# H616 register map
Vendor: Allwinner; Series: H616; File version: 0.1
CPU: other 0, little endian, MPU, no FPU, 0 interrupt priority bits
Registers are 32-bit, read-write, reset 0x0 unless marked. A register's access mark holds for its fields unless they carry their own. Offsets are from the block's base; [hi:lo] are bit positions; lines under a group give offsets from that group; {n}, {i} and the like mark numbered series.

## DMA
Base 0x03002000
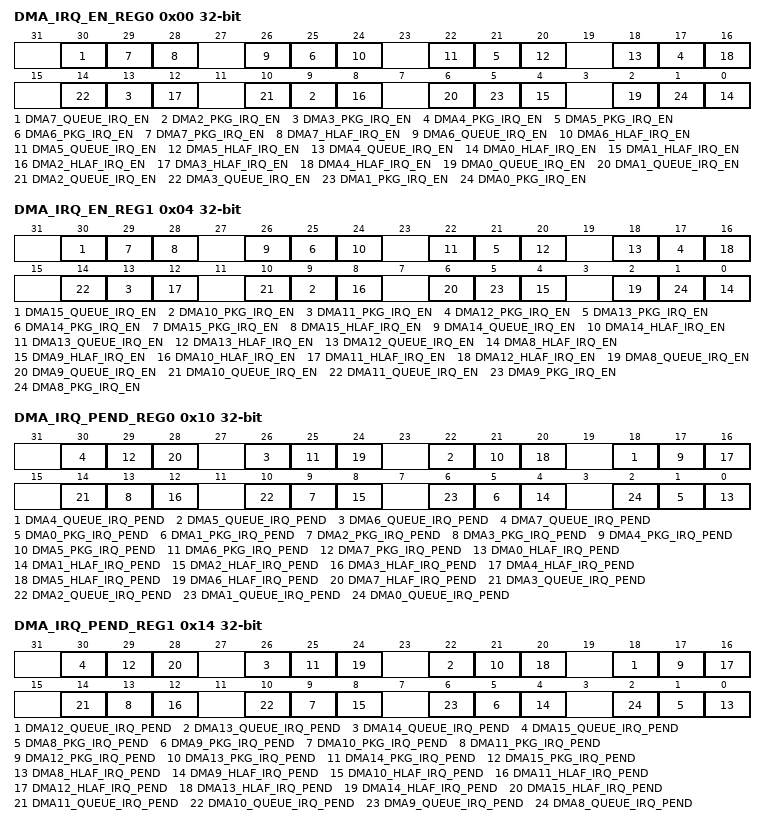
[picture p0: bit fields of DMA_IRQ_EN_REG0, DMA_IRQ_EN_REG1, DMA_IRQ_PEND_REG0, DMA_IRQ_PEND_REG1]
0x00 DMA_IRQ_EN_REG0 — DMA IRQ Enable Register 0
  [all] fields
    0=Disable; 1=Enable
  [30] DMA7_QUEUE_IRQ_EN — DMA 7 Queue End Transfer Interrupt Enable 0: Disable 1: Enable
  [4n+1] DMA{n}_PKG_IRQ_EN (n=2..7) — DMA {n} Package End Transfer Interrupt Enable 0: Disable 1: Enable
  [28] DMA7_HLAF_IRQ_EN — DMA 7 Half Package Transfer Interrupt Enable 0: Disable 1: Enable
  [26] DMA6_QUEUE_IRQ_EN — DMA 6 Queue End Transfer Interrupt Enable 0: Disable 1: Enable
  [24] DMA6_HLAF_IRQ_EN — DMA 6 Half Package Transfer Interrupt Enable 0: Disable 1: Enable
  [22] DMA5_QUEUE_IRQ_EN — DMA 5 Queue End Transfer Interrupt Enable 0: Disable 1: Enable
  [20] DMA5_HLAF_IRQ_EN — DMA 5 Half package Transfer Interrupt Enable 0: Disable 1: Enable
  [18] DMA4_QUEUE_IRQ_EN — DMA 4 Queue End Transfer Interrupt Enable. 0: Disable 1: Enable
  [4n] DMA{n}_HLAF_IRQ_EN (n=0..4) — DMA {n} Half Package Transfer Interrupt Enable 0: Disable 1: Enable
  [4n+2] DMA{n}_QUEUE_IRQ_EN (n=0..3) — DMA {n} Queue End Transfer Interrupt Enable 0: Disable 1: Enable
  [5] DMA1_PKG_IRQ_EN — DMA 1 Package End Transfer Interrupt Enable. 0: Disable 1: Enable
  [1] DMA0_PKG_IRQ_EN — DMA 0 Package End Transfer Interrupt Enable 0: Disable 1: Enable
0x04 DMA_IRQ_EN_REG1 — DMA IRQ Enable Register 1
  [all] fields
    0=Disable; 1=Enable
  [30] DMA15_QUEUE_IRQ_EN — DMA 15 Queue End Transfer Interrupt Enable 0: Disable 1: Enable
  [4n-31] DMA{n}_PKG_IRQ_EN (n=10..15) — DMA {n} Package End Transfer Interrupt Enable 0: Disable 1: Enable
  [28] DMA15_HLAF_IRQ_EN — DMA 15 Half Package Transfer Interrupt Enable 0: Disable 1: Enable
  [26] DMA14_QUEUE_IRQ_EN — DMA 14 Queue End Transfer Interrupt Enable 0: Disable 1: Enable
  [24] DMA14_HLAF_IRQ_EN — DMA 14 Half Package Transfer Interrupt Enable 0: Disable 1: Enable
  [22] DMA13_QUEUE_IRQ_EN — DMA 13 Queue End Transfer Interrupt Enable 0: Disable 1: Enable
  [20] DMA13_HLAF_IRQ_EN — DMA 13 Half package Transfer Interrupt Enable 0: Disable 1: Enable
  [18] DMA12_QUEUE_IRQ_EN — DMA 12 Queue End Transfer Interrupt Enable. 0: Disable 1: Enable
  [4n-32] DMA{n}_HLAF_IRQ_EN (n=8..12) — DMA {n} Half Package Transfer Interrupt Enable 0: Disable 1: Enable
  [4n-30] DMA{n}_QUEUE_IRQ_EN (n=8..11) — DMA {n} Queue End Transfer Interrupt Enable 0: Disable 1: Enable
  [5] DMA9_PKG_IRQ_EN — DMA 9 Package End Transfer Interrupt Enable. 0: Disable 1: Enable
  [1] DMA8_PKG_IRQ_EN — DMA 8 Package End Transfer Interrupt Enable 0: Disable 1: Enable
0x10 DMA_IRQ_PEND_REG0 — DMA IRQ Pending Register 0
  [all] fields
    0=No_effect; 1=Pending
  [4n+2] DMA{n}_QUEUE_IRQ_PEND write-1-clears (n=4..7) — DMA {n} Queue End Transfer Interrupt Pending. Setting 1 to the bit will clear it. 0: No effect 1: Pending
  [4n+1] DMA{n}_PKG_IRQ_PEND write-1-clears (n=0..7) — DMA {n} Package End Transfer Interrupt Pending. Setting 1 to the bit will clear it. 0: No effect 1: Pending
  [4n] DMA{n}_HLAF_IRQ_PEND write-1-clears (n=0..7) — DMA {n} Half Package Transfer Interrupt Pending. Setting 1 to the bit will clear it. 0: No effect 1: Pending
  [14] DMA3_QUEUE_IRQ_PEND write-1-clears — DMA 3 Queue End Transfer Interrupt Pending. Setting 1 to the bit will clear it. 0: No effect 1: Pending.
  [10] DMA2_QUEUE_IRQ_PEND write-1-clears — DMA 2 Queue End Transfer Interrupt Pending. Setting 1 to the bit will clear it. 0: No effect 1: Pending
  [6] DMA1_QUEUE_IRQ_PEND write-1-clears — DMA 1 Queue End Transfer Interrupt Pending. Setting 1 to the bit will clear it. 0: No effect 1: Pending
  [2] DMA0_QUEUE_IRQ_PEND write-1-clears — DMA 0 Queue End Transfer Interrupt Pending. Setting 1 to the bit will clear it. 0: No effect 1: Pending
0x14 DMA_IRQ_PEND_REG1 — DMA IRQ Pending Register 1
  [all] fields
    0=No_effect; 1=Pending
  [4n-30] DMA{n}_QUEUE_IRQ_PEND write-1-clears (n=12..15) — DMA {n} Queue End Transfer Interrupt Pending. Setting 1 to the bit will clear it. 0: No effect 1: Pending
  [4n-31] DMA{n}_PKG_IRQ_PEND write-1-clears (n=8..15) — DMA {n} Package End Transfer Interrupt Pending. Setting 1 to the bit will clear it. 0: No effect 1: Pending
  [4n-32] DMA{n}_HLAF_IRQ_PEND write-1-clears (n=8..15) — DMA {n} Half Package Transfer Interrupt Pending. Setting 1 to the bit will clear it. 0: No effect 1: Pending
  [14] DMA11_QUEUE_IRQ_PEND write-1-clears — DMA 11 Queue End Transfer Interrupt Pending. Setting 1 to the bit will clear it. 0: No effect 1: Pending.
  [10] DMA10_QUEUE_IRQ_PEND write-1-clears — DMA 10 Queue End Transfer Interrupt Pending. Setting 1 to the bit will clear it. 0: No effect 1: Pending
  [6] DMA9_QUEUE_IRQ_PEND write-1-clears — DMA 9 Queue End Transfer Interrupt Pending. Setting 1 to the bit will clear it. 0: No effect 1: Pending
  [2] DMA8_QUEUE_IRQ_PEND write-1-clears — DMA 8 Queue End Transfer Interrupt Pending. Setting 1 to the bit will clear it. 0: No effect 1: Pending
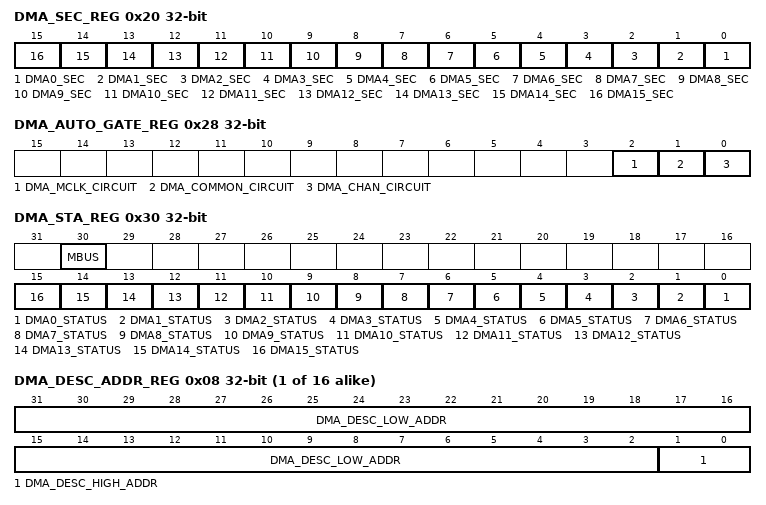
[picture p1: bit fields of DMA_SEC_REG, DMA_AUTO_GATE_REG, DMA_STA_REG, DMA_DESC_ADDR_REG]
0x20 DMA_SEC_REG — DMA Security Register
  [all] fields
    0=Secure; 1=non_secure
  [n] DMA{n}_SEC (n=0..15) — DMA channel {n} security 0: Secure 1: Non-secure
0x28 DMA_AUTO_GATE_REG — DMA Auto Gating Register
  [all] fields
    0=Auto_gating_enable; 1=Auto_gating_disable
  [2] DMA_MCLK_CIRCUIT — DMA MCLK interface circuit auto gating bit 0: Auto gating enable 1: Auto gating disable
  [1] DMA_COMMON_CIRCUIT — DMA common circuit auto gating bit 0: Auto gating enable 1: Auto gating disable
  [0] DMA_CHAN_CIRCUIT — DMA channel circuit auto gating bit 0: Auto gating enable 1: Auto gating disable
0x30 DMA_STA_REG — DMA Status Register
  [30] MBUS ro — FIFO Status 0: Empty 1: Not Empty
    0=Empty; 1=Not_Empty
  [n] DMA{n}_STATUS ro (n=0..15) — DMA Channel {n} Status 0: Idle 1: Busy
    0=Idle; 1=Busy
{0x100+0x40*i} _N[{i}] (i=0..15) group
  0x00 DMA_EN_REG — DMA Channel Enable Register (N=0~15)
    [0] DMA_EN — DMA Channel Enable 0: Disable 1: Enable
      0=Disable; 1=Enable
  0x04 DMA_PAU_REG — DMA Channel Pause Register(N=0~15)
    [0] DMA_PAUSE — Pausing DMA Channel Transfer Data 0: Resume Transferring 1: Pause Transferring
      0=Resume Transferring; 1=Pause Transferring
  0x08 DMA_DESC_ADDR_REG — DMA Channel Start Address Register(N=0~15)
    [31:2] DMA_DESC_LOW_ADDR — DMA Channel Descriptor Word Address, Low 30bits. The Descriptor Address must be word-aligned.
    [1:0] DMA_DESC_HIGH_ADDR — DMA Channel Descriptor High Address, High 2bits The real address is as below: DMA Channel Descriptor Address = {bit[1:0],bit[31:2],2`b00};
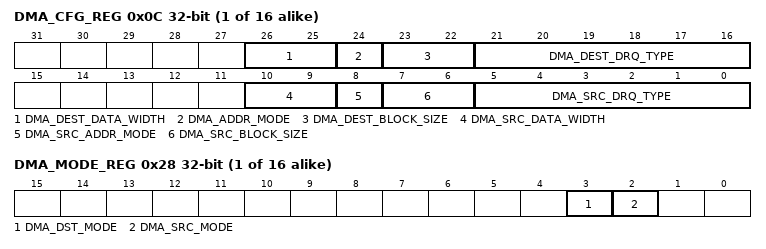
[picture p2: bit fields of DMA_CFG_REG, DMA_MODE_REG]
  0x0C DMA_CFG_REG — DMA Channel Configuration Register(N=0~15)
    [26:25] DMA_DEST_DATA_WIDTH ro — DMA Destination Data Width 00: 8-bit 01: 16-bit 10: 32-bit 11: 64-bit
      0=_8_bit; 1=_16_bit; 2=_32_bit; 3=_64_bit
    [24] DMA_ADDR_MODE ro — DMA Destination Address Mode 0: Linear Mode 1: IO Mode
      0=Linear Mode; 1=IO (IO Mode)
    [23:22] DMA_DEST_BLOCK_SIZE ro — DMA Destination Block Size 00: 1 01: 4 10: 8 11: 16
      0=_1; 1=_4; 2=_8; 3=_16
    [21:16] DMA_DEST_DRQ_TYPE ro — DMA Destination DRQ Type The details in DRQ Type and Port Corresponding Relation.
    [10:9] DMA_SRC_DATA_WIDTH ro — DMA Source Data Width 00: 8-bit 01: 16-bit 10: 32-bit 11: 64-bit
      0=_8_bit; 1=_16_bit; 2=_32_bit; 3=_64_bit
    [8] DMA_SRC_ADDR_MODE ro — DMA Source Address Mode 0: Linear Mode 1: IO Mode
      0=Linear Mode; 1=IO (IO Mode)
    [7:6] DMA_SRC_BLOCK_SIZE ro — DMA Source Block Size 00: 1 01: 4 10: 8 11: 16
      0=_1; 1=_4; 2=_8; 3=_16
    [5:0] DMA_SRC_DRQ_TYPE ro — DMA Source DRQ Type The details in DRQ Type and Port Corresponding Relation.
  0x10 DMA_CUR_SRC_REG — DMA Channel Current Source Register(N=0~15)
    [31:0] DMA_CUR_SRC ro — DMA Channel Current Source Address, read only.
  0x14 DMA_CUR_DEST_REG — DMA Channel Current Destination Register(N=0~15)
    [31:0] DMA_CUR_DEST ro — DMA Channel Current Destination Address, read only.
  0x18 DMA_BCNT_LEFT_REG — DMA Channel Byte Counter Left Register(N=0~15)
    [24:0] DMA_BCNT_LEFT ro — DMA Channel Byte Counter Left, read only.
  0x1C DMA_PARA_REG — DMA Channel Parameter Register(N=0~15)
    [7:0] WAIT_CYC ro — Wait Clock Cycles
  0x28 DMA_MODE_REG — DMA Mode Register(N=0~15)
    [3] DMA_DST_MODE — 0: Wait mode 1: Handshake mode
      0=Wait_mode; 1=Handshake_mode
    [2] DMA_SRC_MODE — 0: Wait mode 1: Handshake mode
      0=Wait_mode; 1=Handshake_mode
  0x2C DMA_FDESC_ADDR_REG — DMA Former Descriptor Address Register(N=0~15)
    [31:0] DMA_FDESC_ADDR ro — This register is used to store the former value of DMA Channel Descriptor Address Register.
  0x30 DMA_PKG_NUM_REG — DMA Package Number Register(N=0~15)
    [31:0] DMA_PKG_NUM ro — This register will record the number of packages which has been completed in one transmission.
